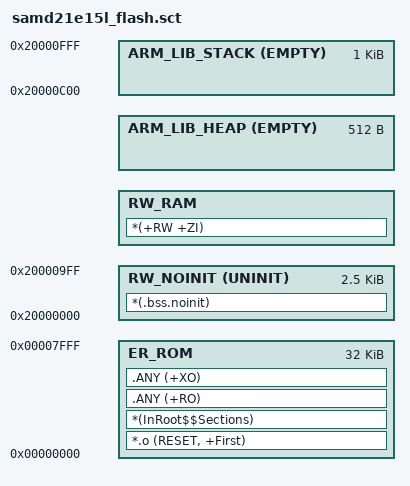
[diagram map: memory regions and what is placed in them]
#! armclang -E --target=arm-arm-none-eabi -mcpu=cortex-m0plus -xc
/* command above MUST be in first line (no comment above!) */

/*
 * ARMCC scatter file (flash) for ATSAMD21E15L
 *
 * Copyright (c) 2025 Microchip Technology Inc. and its subsidiaries
 *
 * SPDX-License-Identifier: Apache-2.0
 *
 * Licensed under the Apache License, Version 2.0 (the "License");
 * you may not use this file except in compliance with the License.
 * You may obtain a copy of the License at
 *
 *   https://www.apache.org/licenses/LICENSE-2.0
 *
 * Unless required by applicable law or agreed to in writing, software
 * distributed under the License is distributed on an "AS IS" BASIS,
 * WITHOUT WARRANTIES OR CONDITIONS OF ANY KIND, either express or implied.
 * See the License for the specific language governing permissions and
 * limitations under the License.
 *
 */

/*------------------------------------------------------------------------------
 *            Scatter file script for running code on the ATSAMD21E15L           
 *-----------------------------------------------------------------------------*/

/*------------------ <<< start of configuration section >>> ------------------*/
#ifndef ROM_ORIGIN
#  define ROM_ORIGIN 0x00000000
#endif

#ifndef ROM_LENGTH
#  define ROM_LENGTH 0x8000 /* ROM, 32 KB */
#elif (ROM_LENGTH > 0x8000)
#  error ROM_LENGTH is greater than the max size of 0x8000
#endif

#ifndef RAM_ORIGIN
#  define RAM_ORIGIN 0x20000000
#endif

#ifndef RAM_LENGTH
#  define RAM_LENGTH 0x1000 /* RAM, 4 KB */
#elif (RAM_LENGTH > 0x1000)
#  error RAM_LENGTH is greater than the max size of 0x1000
#endif

/*--------------------------- Flash Configuration ----------------------------*/
#define __ROM_BASE  ROM_ORIGIN
#define __ROM_SIZE  ROM_LENGTH

/*------------------------ Embedded RAM Configuration ------------------------*/
#define __RAM_BASE  RAM_ORIGIN
#define __RAM_SIZE  RAM_LENGTH


/*------------------------ Stack / Heap Configuration ------------------------*/
#define __STACK_SIZE    0x0400
#define __HEAP_SIZE     0x0200

/*------------------- <<< end of configuration section >>> -------------------*/


/*------------------------------------------------------------------------------
 *                     User Stack & Heap boundary definition                     
 *-----------------------------------------------------------------------------*/
#define __STACK_TOP    (__RAM_BASE + __RAM_SIZE) /* starts at end of RAM - 8 byte stack seal */
#define __HEAP_BASE    (AlignExpr(+0, 8))        /* starts after RW_RAM section, 8 byte aligned */

/*------------------------------------------------------------------------------
 *                         Region base & size definition                         
 *-----------------------------------------------------------------------------*/
#define __RO_BASE          (__ROM_BASE)
#define __RO_SIZE          (__ROM_SIZE)

#define __RW_BASE          (__RAM_BASE)
#define __RW_SIZE      (__RAM_SIZE - __STACK_SIZE - __HEAP_SIZE)

/*------------------------------------------------------------------------------
 *                           Scatter Region definition                           
 *-----------------------------------------------------------------------------*/
LR_ROM __RO_BASE __RO_SIZE  {                       ; load region size_region
    ER_ROM __RO_BASE __RO_SIZE  {                   ; load address = execution address
        *.o (RESET, +First)
        *(InRoot$$Sections)
        .ANY (+RO)
        .ANY (+XO)
    }

    RW_NOINIT __RW_BASE UNINIT __RW_SIZE {
        *(.bss.noinit)
    }

    RW_RAM AlignExpr(+0, 8) (__RW_SIZE - AlignExpr(ImageLength(RW_NOINIT), 8)) {
        *(+RW +ZI)
    }

#if __HEAP_SIZE > 0
    ARM_LIB_HEAP  __HEAP_BASE EMPTY  __HEAP_SIZE  {   ; Reserve empty region for heap
    }
#endif

    ARM_LIB_STACK __STACK_TOP EMPTY -__STACK_SIZE {   ; Reserve empty region for stack
    }
}
